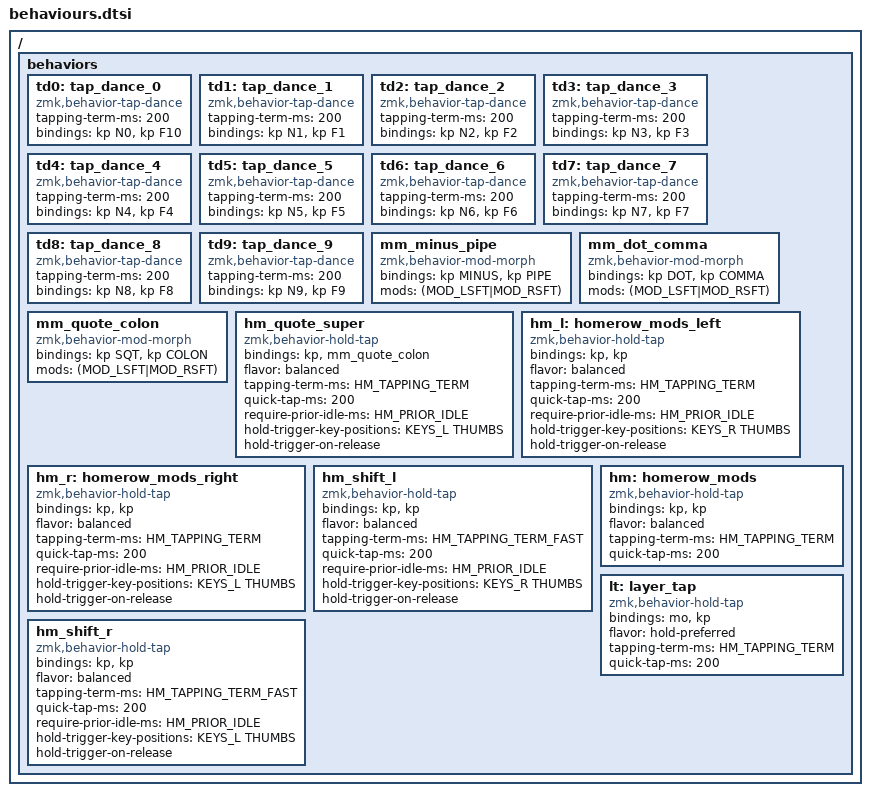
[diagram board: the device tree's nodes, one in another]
#include "zmk-helpers/helper.h"
#include <behaviors.dtsi>
#include <dt-bindings/zmk/bt.h>
#include <dt-bindings/zmk/keys.h>
#include <dt-bindings/zmk/outputs.h>
#include <dt-bindings/zmk/ext_power.h>
#include <dt-bindings/zmk/pointing.h>

#define HM_TAPPING_TERM               250
#define HM_TAPPING_REPEAT             210
#define HM_TAPPING_TERM_FAST          200
#define HM_PRIOR_IDLE                 70

/ {
    behaviors {
        td0: tap_dance_0 {
            compatible = "zmk,behavior-tap-dance";
            #binding-cells = <0>;
            tapping-term-ms = <200>;
            bindings = <&kp N0>, <&kp F10>;
        };
        td1: tap_dance_1 {
            compatible = "zmk,behavior-tap-dance";
            #binding-cells = <0>;
            tapping-term-ms = <200>;
            bindings = <&kp N1>, <&kp F1>;
        };
        td2: tap_dance_2 {
            compatible = "zmk,behavior-tap-dance";
            #binding-cells = <0>;
            tapping-term-ms = <200>;
            bindings = <&kp N2>, <&kp F2>;
        };
        td3: tap_dance_3 {
            compatible = "zmk,behavior-tap-dance";
            #binding-cells = <0>;
            tapping-term-ms = <200>;
            bindings = <&kp N3>, <&kp F3>;
        };
        td4: tap_dance_4 {
            compatible = "zmk,behavior-tap-dance";
            #binding-cells = <0>;
            tapping-term-ms = <200>;
            bindings = <&kp N4>, <&kp F4>;
        };
        td5: tap_dance_5 {
            compatible = "zmk,behavior-tap-dance";
            #binding-cells = <0>;
            tapping-term-ms = <200>;
            bindings = <&kp N5>, <&kp F5>;
        };
        td6: tap_dance_6 {
            compatible = "zmk,behavior-tap-dance";
            #binding-cells = <0>;
            tapping-term-ms = <200>;
            bindings = <&kp N6>, <&kp F6>;
        };
        td7: tap_dance_7 {
            compatible = "zmk,behavior-tap-dance";
            #binding-cells = <0>;
            tapping-term-ms = <200>;
            bindings = <&kp N7>, <&kp F7>;
        };
        td8: tap_dance_8 {
            compatible = "zmk,behavior-tap-dance";
            #binding-cells = <0>;
            tapping-term-ms = <200>;
            bindings = <&kp N8>, <&kp F8>;
        };
        td9: tap_dance_9 {
            compatible = "zmk,behavior-tap-dance";
            #binding-cells = <0>;
            tapping-term-ms = <200>;
            bindings = <&kp N9>, <&kp F9>;
        };

        mm_minus_pipe: mm_minus_pipe {
            compatible = "zmk,behavior-mod-morph";
            #binding-cells = <0>;
            bindings = <&kp MINUS>, <&kp PIPE>;
            mods = <(MOD_LSFT|MOD_RSFT)>;
        };
        mm_dot_comma: mm_dot_comma {
            compatible = "zmk,behavior-mod-morph";
            #binding-cells = <0>;
            bindings = <&kp DOT>, <&kp COMMA>;
            mods = <(MOD_LSFT|MOD_RSFT)>;
        };
        mm_quote_colon: mm_quote_colon {
            compatible = "zmk,behavior-mod-morph";
            #binding-cells = <0>;
            bindings = <&kp SQT>, <&kp COLON>;
            mods = <(MOD_LSFT|MOD_RSFT)>;
        };
        hm_quote_super: hm_quote_super {
            compatible = "zmk,behavior-hold-tap";
            #binding-cells = <2>;
            bindings = <&kp>, <&mm_quote_colon>;

            flavor = "balanced";
            tapping-term-ms = <HM_TAPPING_TERM>;
            quick-tap-ms = <200>;
            require-prior-idle-ms = <HM_PRIOR_IDLE>;
            hold-trigger-key-positions = <KEYS_L THUMBS>;
            hold-trigger-on-release;
        };
        hm_l: homerow_mods_left {
            compatible = "zmk,behavior-hold-tap";
            #binding-cells = <2>;
            bindings = <&kp>, <&kp>;

            flavor = "balanced";
            tapping-term-ms = <HM_TAPPING_TERM>;
            quick-tap-ms = <200>;                // repeat on tap-into-hold
            require-prior-idle-ms = <HM_PRIOR_IDLE>;
            hold-trigger-key-positions = <KEYS_R THUMBS>;
            hold-trigger-on-release;
        };

        hm_r: homerow_mods_right {
            compatible = "zmk,behavior-hold-tap";
            #binding-cells = <2>;
            bindings = <&kp>, <&kp>;

            flavor = "balanced";
            tapping-term-ms = <HM_TAPPING_TERM>;
            quick-tap-ms = <200>;
            require-prior-idle-ms = <HM_PRIOR_IDLE>;
            hold-trigger-key-positions = <KEYS_L THUMBS>;
            hold-trigger-on-release;
        };

        // Positional Homerow mods for shift
        // Use faster tapping term and disable some features that may
        // cause false negatives.

        hm_shift_l: hm_shift_l {
            compatible = "zmk,behavior-hold-tap";
            #binding-cells = <2>;
            bindings = <&kp>, <&kp>;

            //flavor = "balanced";

            flavor = "balanced";
            tapping-term-ms = <HM_TAPPING_TERM_FAST>;
            quick-tap-ms = <200>;
            require-prior-idle-ms = <HM_PRIOR_IDLE>;
            hold-trigger-key-positions = <KEYS_R THUMBS>;
            hold-trigger-on-release;
        };

        hm_shift_r: hm_shift_r {
            compatible = "zmk,behavior-hold-tap";
            #binding-cells = <2>;
            bindings = <&kp>, <&kp>;

            flavor = "balanced";
            tapping-term-ms = <HM_TAPPING_TERM_FAST>;
            quick-tap-ms = <200>;
            require-prior-idle-ms = <HM_PRIOR_IDLE>;
            hold-trigger-key-positions = <KEYS_L THUMBS>;

            // for quick tapping; shift+~

            hold-trigger-on-release;
        };

        /*
         * Non-Positional Homerow Mods
         * Used for &mm_grescm_gui behavior on left hand.
         *
         * Usage: &hm LSHFT T
         * Tap: T
         * Tap-Tap-Hold: Repeat T
         * Hold: LSHIFT
         */

        hm: homerow_mods {
            compatible = "zmk,behavior-hold-tap";
            #binding-cells = <2>;
            bindings = <&kp>, <&kp>;

            flavor = "balanced";
            tapping-term-ms = <HM_TAPPING_TERM>;
            quick-tap-ms = <200>;
        };

        lt: layer_tap {
            compatible = "zmk,behavior-hold-tap";
            #binding-cells = <2>;
            bindings = <&mo>, <&kp>;

            flavor = "hold-preferred";
            tapping-term-ms = <HM_TAPPING_TERM>;
            quick-tap-ms = <200>;
        };
    };
};
